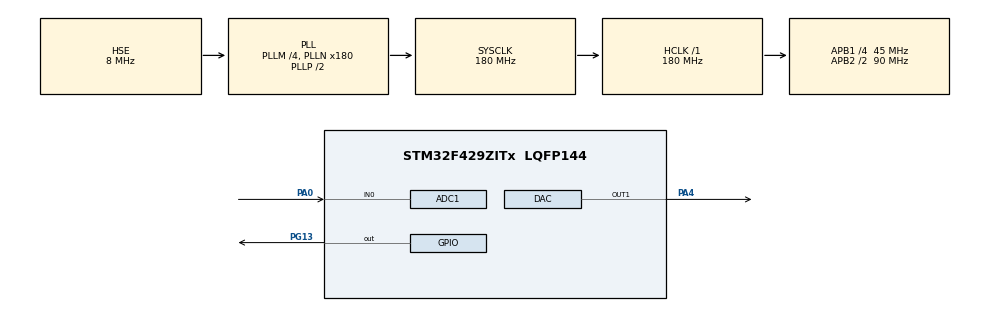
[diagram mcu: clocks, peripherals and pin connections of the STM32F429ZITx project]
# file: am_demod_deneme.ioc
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ADC1.Channel-0\#ChannelRegularConversion=ADC_CHANNEL_0
ADC1.ExternalTrigConv=ADC_EXTERNALTRIGCONV_T2_TRGO
ADC1.NbrOfConversionFlag=1
ADC1.Rank-0\#ChannelRegularConversion=1
ADC1.SamplingTime-0\#ChannelRegularConversion=ADC_SAMPLETIME_28CYCLES
ADC1.master=1
Mcu.Family=STM32F4
Mcu.Name=STM32F429ZITx
Mcu.Package=LQFP144
NVIC.ADC_IRQn=true\:0\:0\:false\:false\:true\:true\:true
NVIC.PriorityGroup=NVIC_PRIORITYGROUP_4
NVIC.TIM2_IRQn=true\:0\:0\:false\:false\:true\:true\:true
PA0/WKUP.Signal=ADCx_IN0
PA4.Signal=COMP_DAC1_group
PG13.GPIO_Speed=GPIO_SPEED_FREQ_VERY_HIGH
PG13.Signal=GPIO_Output
PH0/OSC_IN.Mode=HSE-External-Oscillator
PH0/OSC_IN.Signal=RCC_OSC_IN
PH1/OSC_OUT.Mode=HSE-External-Oscillator
PH1/OSC_OUT.Signal=RCC_OSC_OUT
ProjectManager.HeapSize=0x200
ProjectManager.StackSize=0x400
ProjectManager.TargetToolchain=MDK-ARM V5
RCC.48MHZClocksFreq_Value=90000000
RCC.AHBFreq_Value=180000000
RCC.APB1CLKDivider=RCC_HCLK_DIV4
RCC.APB1Freq_Value=45000000
RCC.APB1TimFreq_Value=90000000
RCC.APB2CLKDivider=RCC_HCLK_DIV2
RCC.APB2Freq_Value=90000000
RCC.APB2TimFreq_Value=180000000
RCC.CortexFreq_Value=180000000
RCC.HCLKFreq_Value=180000000
RCC.HSE_VALUE=8000000
RCC.HSI_VALUE=16000000
RCC.LSE_VALUE=32768
RCC.PLLM=4
RCC.PLLN=180
RCC.PLLSourceVirtual=RCC_PLLSOURCE_HSE
RCC.SYSCLKFreq_VALUE=180000000
RCC.SYSCLKSource=RCC_SYSCLKSOURCE_PLLCLK
RCC.VCOOutputFreq_Value=360000000
SH.ADCx_IN0.0=ADC1_IN0,IN0
SH.COMP_DAC1_group.0=DAC_OUT1,DAC_OUT1
TIM2.Period=9
TIM2.Prescaler=33
VP_TIM2_VS_ClockSourceINT.Mode=Internal
board=custom

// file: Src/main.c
/* USER CODE BEGIN Header */
/**
  ******************************************************************************
  * @file           : main.c
  * @brief          : Main program body
  ******************************************************************************
  * @attention
  *
  * <h2><center>&copy; Copyright (c) 2020 STMicroelectronics.
  * All rights reserved.</center></h2>
  *
  * This software component is licensed by ST under BSD 3-Clause license,
  * the "License"; You may not use this file except in compliance with the
  * License. You may obtain a copy of the License at:
  *                        opensource.org/licenses/BSD-3-Clause
  *
  ******************************************************************************
  */
/* USER CODE END Header */

#include "main.h"

/* USER CODE BEGIN Includes */
//#include "stm32f4xx_hal.h"

/* USER CODE END Includes */

ADC_HandleTypeDef hadc1;

DAC_HandleTypeDef hdac;

TIM_HandleTypeDef htim2;

void SystemClock_Config(void);
static void MX_GPIO_Init(void);
static void MX_ADC1_Init(void);
static void MX_DAC_Init(void);
static void MX_TIM2_Init(void);
/* USER CODE BEGIN PFP */

    float AdcVal = 0;
		float InfoVal = 0;
		uint8_t i = 0;

		float k[16] = {0.0625, 0.0625, 0.0625, 0.0625, 0.0625, 0.0625, 0.0625, 0.0625,
									 0.0625, 0.0625, 0.0625, 0.0625, 0.0625, 0.0625, 0.0625, 0.0625};

		float Carrier[16] = {1, 0, -1, 0, 1, 0, -1, 0, 1, 0, -1, 0, 1, 0, -1, 0};

		float Adum[16] = { 0 };
		float Bdum[16] = { 0 };
		float sumBdum = 0;

/* USER CODE END PFP */

int main(void)
{

  /* MCU Configuration--------------------------------------------------------*/

  /* Reset of all peripherals, Initializes the Flash interface and the Systick. */
  HAL_Init();

  /* Configure the system clock */
  SystemClock_Config();

  /* Initialize all configured peripherals */
  MX_GPIO_Init();
  MX_ADC1_Init();
  MX_DAC_Init();
  MX_TIM2_Init();
  /* USER CODE BEGIN 2 */

   HAL_TIM_Base_Start_IT(&htim2);
   HAL_ADC_Start_IT(&hadc1);
   HAL_DAC_Start(&hdac, DAC_CHANNEL_1);

  /* USER CODE END 2 */

  /* Infinite loop */
  while (1)
  {

  }
}

void SystemClock_Config(void)
{
  RCC_OscInitTypeDef RCC_OscInitStruct = {0};
  RCC_ClkInitTypeDef RCC_ClkInitStruct = {0};

  /** Configure the main internal regulator output voltage
  */
  __HAL_RCC_PWR_CLK_ENABLE();
  __HAL_PWR_VOLTAGESCALING_CONFIG(PWR_REGULATOR_VOLTAGE_SCALE1);
  /** Initializes the CPU, AHB and APB busses clocks
  */
  RCC_OscInitStruct.OscillatorType = RCC_OSCILLATORTYPE_HSE;
  RCC_OscInitStruct.HSEState = RCC_HSE_ON;
  RCC_OscInitStruct.PLL.PLLState = RCC_PLL_ON;
  RCC_OscInitStruct.PLL.PLLSource = RCC_PLLSOURCE_HSE;
  RCC_OscInitStruct.PLL.PLLM = 4;
  RCC_OscInitStruct.PLL.PLLN = 180;
  RCC_OscInitStruct.PLL.PLLP = RCC_PLLP_DIV2;
  RCC_OscInitStruct.PLL.PLLQ = 4;
  if (HAL_RCC_OscConfig(&RCC_OscInitStruct) != HAL_OK)
  {
    Error_Handler();
  }
  /** Activate the Over-Drive mode
  */
  if (HAL_PWREx_EnableOverDrive() != HAL_OK)
  {
    Error_Handler();
  }
  /** Initializes the CPU, AHB and APB busses clocks
  */
  RCC_ClkInitStruct.ClockType = RCC_CLOCKTYPE_HCLK|RCC_CLOCKTYPE_SYSCLK
                              |RCC_CLOCKTYPE_PCLK1|RCC_CLOCKTYPE_PCLK2;
  RCC_ClkInitStruct.SYSCLKSource = RCC_SYSCLKSOURCE_PLLCLK;
  RCC_ClkInitStruct.AHBCLKDivider = RCC_SYSCLK_DIV1;
  RCC_ClkInitStruct.APB1CLKDivider = RCC_HCLK_DIV4;
  RCC_ClkInitStruct.APB2CLKDivider = RCC_HCLK_DIV2;

  if (HAL_RCC_ClockConfig(&RCC_ClkInitStruct, FLASH_LATENCY_5) != HAL_OK)
  {
    Error_Handler();
  }
}

static void MX_ADC1_Init(void)
{

  ADC_ChannelConfTypeDef sConfig = {0};

  /** Configure the global features of the ADC (Clock, Resolution, Data Alignment and number of conversion)
  */
  hadc1.Instance = ADC1;
  hadc1.Init.ClockPrescaler = ADC_CLOCK_SYNC_PCLK_DIV4;
  hadc1.Init.Resolution = ADC_RESOLUTION_12B;
  hadc1.Init.ScanConvMode = DISABLE;
  hadc1.Init.ContinuousConvMode = DISABLE;
  hadc1.Init.DiscontinuousConvMode = DISABLE;
  hadc1.Init.ExternalTrigConvEdge = ADC_EXTERNALTRIGCONVEDGE_RISING;
  hadc1.Init.ExternalTrigConv = ADC_EXTERNALTRIGCONV_T2_TRGO;
  hadc1.Init.DataAlign = ADC_DATAALIGN_RIGHT;
  hadc1.Init.NbrOfConversion = 1;
  hadc1.Init.DMAContinuousRequests = DISABLE;
  hadc1.Init.EOCSelection = ADC_EOC_SINGLE_CONV;
  if (HAL_ADC_Init(&hadc1) != HAL_OK)
  {
    Error_Handler();
  }
  /** Configure for the selected ADC regular channel its corresponding rank in the sequencer and its sample time.
  */
  sConfig.Channel = ADC_CHANNEL_0;
  sConfig.Rank = 1;
  sConfig.SamplingTime = ADC_SAMPLETIME_28CYCLES;
  if (HAL_ADC_ConfigChannel(&hadc1, &sConfig) != HAL_OK)
  {
    Error_Handler();
  }

}

static void MX_DAC_Init(void)
{

  DAC_ChannelConfTypeDef sConfig = {0};

  /** DAC Initialization
  */
  hdac.Instance = DAC;
  if (HAL_DAC_Init(&hdac) != HAL_OK)
  {
    Error_Handler();
  }
  /** DAC channel OUT1 config
  */
  sConfig.DAC_Trigger = DAC_TRIGGER_NONE;
  sConfig.DAC_OutputBuffer = DAC_OUTPUTBUFFER_ENABLE;
  if (HAL_DAC_ConfigChannel(&hdac, &sConfig, DAC_CHANNEL_1) != HAL_OK)
  {
    Error_Handler();
  }

}

static void MX_TIM2_Init(void)
{

  TIM_ClockConfigTypeDef sClockSourceConfig = {0};
  TIM_MasterConfigTypeDef sMasterConfig = {0};

  htim2.Instance = TIM2;
  htim2.Init.Prescaler = 180;
  htim2.Init.CounterMode = TIM_COUNTERMODE_UP;
  htim2.Init.Period = 9;
  htim2.Init.ClockDivision = TIM_CLOCKDIVISION_DIV1;
  htim2.Init.AutoReloadPreload = TIM_AUTORELOAD_PRELOAD_DISABLE;
  if (HAL_TIM_Base_Init(&htim2) != HAL_OK)
  {
    Error_Handler();
  }
  sClockSourceConfig.ClockSource = TIM_CLOCKSOURCE_INTERNAL;
  if (HAL_TIM_ConfigClockSource(&htim2, &sClockSourceConfig) != HAL_OK)
  {
    Error_Handler();
  }
  sMasterConfig.MasterOutputTrigger = TIM_TRGO_RESET;
  sMasterConfig.MasterSlaveMode = TIM_MASTERSLAVEMODE_DISABLE;
  if (HAL_TIMEx_MasterConfigSynchronization(&htim2, &sMasterConfig) != HAL_OK)
  {
    Error_Handler();
  }

}

static void MX_GPIO_Init(void)
{
  GPIO_InitTypeDef GPIO_InitStruct = {0};

  /* GPIO Ports Clock Enable */
  __HAL_RCC_GPIOH_CLK_ENABLE();
  __HAL_RCC_GPIOA_CLK_ENABLE();
  __HAL_RCC_GPIOG_CLK_ENABLE();

  /*Configure GPIO pin Output Level */
  HAL_GPIO_WritePin(GPIOG, GPIO_PIN_13, GPIO_PIN_RESET);

  /*Configure GPIO pin : PG13 */
  GPIO_InitStruct.Pin = GPIO_PIN_13;
  GPIO_InitStruct.Mode = GPIO_MODE_OUTPUT_PP;
  GPIO_InitStruct.Pull = GPIO_NOPULL;
  GPIO_InitStruct.Speed = GPIO_SPEED_FREQ_VERY_HIGH;
  HAL_GPIO_Init(GPIOG, &GPIO_InitStruct);

}

/* USER CODE BEGIN 4 */
void HAL_TIM_PeriodElapsedCallback(TIM_HandleTypeDef *htim)
{
if(htim->Instance == TIM2)
{
			AdcVal = HAL_ADC_GetValue(&hadc1);

			if(i % 2 == 0) HAL_GPIO_TogglePin(GPIOG, GPIO_PIN_13);

			Adum[15-i] = AdcVal * Carrier[i];

			sumBdum = Adum[15-i] + sumBdum - Bdum[15-i];

			Bdum[15-i] = Adum[15-i];

			InfoVal = sumBdum ;

			HAL_DAC_SetValue(&hdac, DAC_CHANNEL_1, DAC_ALIGN_12B_R, InfoVal);

			i += 1;

			if (i==15) i=0;

}

}
/* USER CODE END 4 */

void Error_Handler(void)
{
}

/************************ (C) COPYRIGHT STMicroelectronics *****END OF FILE****/
